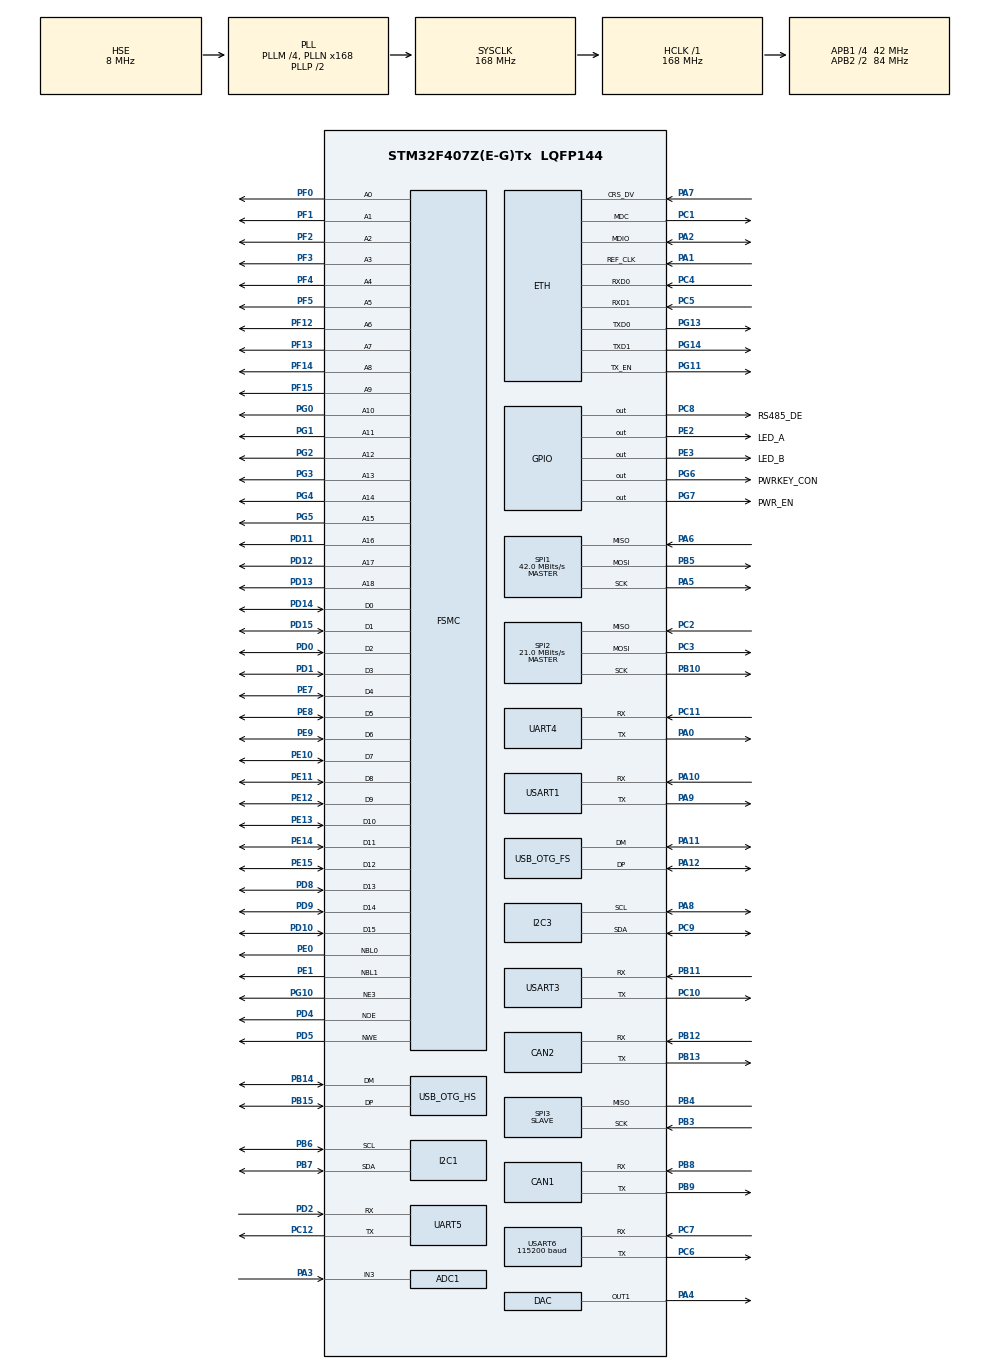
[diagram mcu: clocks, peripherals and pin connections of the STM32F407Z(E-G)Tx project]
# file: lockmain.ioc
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ADC1.Channel-0\#ChannelRegularConversion=ADC_CHANNEL_3
ADC1.NbrOfConversionFlag=1
ADC1.Rank-0\#ChannelRegularConversion=1
ADC1.SamplingTime-0\#ChannelRegularConversion=ADC_SAMPLETIME_3CYCLES
ADC1.master=1
CAN1.CalculateTimeQuantum=380.95238095238096
CAN2.CalculateTimeQuantum=380.95238095238096
ETH.MediaInterface=ETH_MEDIA_INTERFACE_RMII
FREERTOS.BinarySemaphores01=myBinarySem01,Dynamic,NULL
FREERTOS.CountingSemaphores01=myCountingSem01,2,Dynamic,NULL
FREERTOS.HEAP_NUMBER=4
FREERTOS.INCLUDE_eTaskGetState=1
FREERTOS.INCLUDE_pcTaskGetTaskName=1
FREERTOS.INCLUDE_uxTaskGetStackHighWaterMark=1
FREERTOS.INCLUDE_vTaskCleanUpResources=1
FREERTOS.INCLUDE_vTaskDelayUntil=1
FREERTOS.INCLUDE_xEventGroupSetBitFromISR=1
FREERTOS.INCLUDE_xQueueGetMutexHolder=1
FREERTOS.INCLUDE_xSemaphoreGetMutexHolder=1
FREERTOS.INCLUDE_xTaskAbortDelay=1
FREERTOS.INCLUDE_xTaskGetCurrentTaskHandle=1
FREERTOS.INCLUDE_xTaskGetHandle=1
FREERTOS.INCLUDE_xTimerPendFunctionCall=1
FREERTOS.Mutexes01=myMutex01,Dynamic,NULL
FREERTOS.Queues01=defaultQueue,16,uint16_t,0,Dynamic,NULL,NULL
FREERTOS.Tasks01=defaultTask,24,128,StartDefaultTask,Default,NULL,Dynamic,NULL,NULL
FREERTOS.Timers01=defultTimer01,Callback01,osTimerPeriodic,Default,NULL,Dynamic,NULL
FREERTOS.configGENERATE_RUN_TIME_STATS=1
FREERTOS.configUSE_STATS_FORMATTING_FUNCTIONS=1
FREERTOS.configUSE_TICKLESS_IDLE=1
FREERTOS.configUSE_TRACE_FACILITY=1
Mcu.Family=STM32F4
Mcu.Name=STM32F407Z(E-G)Tx
Mcu.Package=LQFP144
NVIC.PriorityGroup=NVIC_PRIORITYGROUP_4
NVIC.TIM8_TRG_COM_TIM14_IRQn=true\:0\:0\:false\:false\:true\:false\:false\:true
NVIC.TimeBase=TIM8_TRG_COM_TIM14_IRQn
NVIC.TimeBaseIP=TIM14
NVIC.UART4_IRQn=true\:5\:0\:false\:false\:true\:true\:true\:true
NVIC.USART1_IRQn=true\:5\:0\:false\:false\:true\:true\:true\:true
NVIC.USART6_IRQn=true\:5\:0\:false\:false\:true\:true\:true\:true
PA0-WKUP.Mode=Asynchronous
PA0-WKUP.Signal=UART4_TX
PA1.Mode=RMII
PA1.Signal=ETH_REF_CLK
PA10.Mode=Asynchronous
PA10.Signal=USART1_RX
PA11.Mode=Host_Only
PA11.Signal=USB_OTG_FS_DM
PA12.Mode=Host_Only
PA12.Signal=USB_OTG_FS_DP
PA13.Mode=Serial_Wire
PA13.Signal=SYS_JTMS-SWDIO
PA14.Mode=Serial_Wire
PA14.Signal=SYS_JTCK-SWCLK
PA2.Mode=RMII
PA2.Signal=ETH_MDIO
PA3.Signal=ADCx_IN3
PA4.Signal=COMP_DAC1_group
PA5.Mode=Full_Duplex_Master
PA5.Signal=SPI1_SCK
PA6.Mode=Full_Duplex_Master
PA6.Signal=SPI1_MISO
PA7.Mode=RMII
PA7.Signal=ETH_CRS_DV
PA8.Mode=I2C
PA8.Signal=I2C3_SCL
PA9.Mode=Asynchronous
PA9.Signal=USART1_TX
PB10.Mode=Full_Duplex_Master
PB10.Signal=SPI2_SCK
PB11.Mode=Asynchronous
PB11.Signal=USART3_RX
PB12.Mode=Slave
PB12.Signal=CAN2_RX
PB13.Mode=Slave
PB13.Signal=CAN2_TX
PB14.Mode=Device_Only_FS
PB14.Signal=USB_OTG_HS_DM
PB15.Mode=Device_Only_FS
PB15.Signal=USB_OTG_HS_DP
PB3.Mode=Simplex_Bidirectional_Slave
PB3.Signal=SPI3_SCK
PB4.Mode=Simplex_Bidirectional_Slave
PB4.Signal=SPI3_MISO
PB5.Mode=Full_Duplex_Master
PB5.Signal=SPI1_MOSI
PB6.Mode=I2C
PB6.Signal=I2C1_SCL
PB7.Mode=I2C
PB7.Signal=I2C1_SDA
PB8.Mode=Master
PB8.Signal=CAN1_RX
PB9.Mode=Master
PB9.Signal=CAN1_TX
PC1.Mode=RMII
PC1.Signal=ETH_MDC
PC10.Mode=Asynchronous
PC10.Signal=USART3_TX
PC11.Mode=Asynchronous
PC11.Signal=UART4_RX
PC12.Mode=Asynchronous
PC12.Signal=UART5_TX
PC14-OSC32_IN.Mode=LSE-External-Oscillator
PC14-OSC32_IN.Signal=RCC_OSC32_IN
PC15-OSC32_OUT.Mode=LSE-External-Oscillator
PC15-OSC32_OUT.Signal=RCC_OSC32_OUT
PC2.Mode=Full_Duplex_Master
PC2.Signal=SPI2_MISO
PC3.Mode=Full_Duplex_Master
PC3.Signal=SPI2_MOSI
PC4.Mode=RMII
PC4.Signal=ETH_RXD0
PC5.Mode=RMII
PC5.Signal=ETH_RXD1
PC6.Mode=Asynchronous
PC6.Signal=USART6_TX
PC7.Mode=Asynchronous
PC7.Signal=USART6_RX
PC8.GPIO_Label=RS485_DE
PC8.Signal=GPIO_Output
PC9.Mode=I2C
PC9.Signal=I2C3_SDA
PD0.Signal=FSMC_D2_DA2
PD1.Signal=FSMC_D3_DA3
PD10.Signal=FSMC_D15_DA15
PD11.Signal=FSMC_A16_CLE
PD12.Signal=FSMC_A17_ALE
PD13.Signal=FSMC_A18
PD14.Signal=FSMC_D0_DA0
PD15.Signal=FSMC_D1_DA1
PD2.Mode=Asynchronous
PD2.Signal=UART5_RX
PD4.Signal=FSMC_NOE
PD5.Signal=FSMC_NWE
PD8.Signal=FSMC_D13_DA13
PD9.Signal=FSMC_D14_DA14
PE0.Signal=FSMC_NBL0
PE1.Signal=FSMC_NBL1
PE10.Signal=FSMC_D7_DA7
PE11.Signal=FSMC_D8_DA8
PE12.Signal=FSMC_D9_DA9
PE13.Signal=FSMC_D10_DA10
PE14.Signal=FSMC_D11_DA11
PE15.Signal=FSMC_D12_DA12
PE2.GPIO_Label=LED_A
PE2.Signal=GPIO_Output
PE3.GPIO_Label=LED_B
PE3.Signal=GPIO_Output
PE7.Signal=FSMC_D4_DA4
PE8.Signal=FSMC_D5_DA5
PE9.Signal=FSMC_D6_DA6
PF0.Signal=FSMC_A0
PF1.Signal=FSMC_A1
PF12.Signal=FSMC_A6
PF13.Signal=FSMC_A7
PF14.Signal=FSMC_A8
PF15.Signal=FSMC_A9
PF2.Signal=FSMC_A2
PF3.Signal=FSMC_A3
PF4.Signal=FSMC_A4
PF5.Signal=FSMC_A5
PG0.Signal=FSMC_A10
PG1.Signal=FSMC_A11
PG10.Mode=NorPsramChipSelect3_1
PG10.Signal=FSMC_NE3
PG11.Mode=RMII
PG11.Signal=ETH_TX_EN
PG13.Mode=RMII
PG13.Signal=ETH_TXD0
PG14.Mode=RMII
PG14.Signal=ETH_TXD1
PG2.Signal=FSMC_A12
PG3.Signal=FSMC_A13
PG4.Signal=FSMC_A14
PG5.Signal=FSMC_A15
PG6.GPIO_Label=PWRKEY_CON
PG6.Signal=GPIO_Output
PG7.GPIO_Label=PWR_EN
PG7.Signal=GPIO_Output
PH0-OSC_IN.Mode=HSE-External-Oscillator
PH0-OSC_IN.Signal=RCC_OSC_IN
PH1-OSC_OUT.Mode=HSE-External-Oscillator
PH1-OSC_OUT.Signal=RCC_OSC_OUT
ProjectManager.HeapSize=0x200
ProjectManager.StackSize=0x400
ProjectManager.TargetToolchain=MDK-ARM V5
RCC.48MHZClocksFreq_Value=48000000
RCC.AHBFreq_Value=168000000
RCC.APB1CLKDivider=RCC_HCLK_DIV4
RCC.APB1Freq_Value=42000000
RCC.APB1TimFreq_Value=84000000
RCC.APB2CLKDivider=RCC_HCLK_DIV2
RCC.APB2Freq_Value=84000000
RCC.APB2TimFreq_Value=168000000
RCC.CortexFreq_Value=168000000
RCC.HCLKFreq_Value=168000000
RCC.HSE_VALUE=8000000
RCC.HSI_VALUE=16000000
RCC.PLLM=4
RCC.PLLN=168
RCC.PLLQ=7
RCC.RCC_RTC_Clock_Source=RCC_RTCCLKSOURCE_LSE
RCC.RCC_RTC_Clock_SourceVirtual=RCC_RTCCLKSOURCE_LSE
RCC.SYSCLKFreq_VALUE=168000000
RCC.SYSCLKSource=RCC_SYSCLKSOURCE_PLLCLK
RCC.VCOOutputFreq_Value=336000000
SH.ADCx_IN3.0=ADC1_IN3,IN3
SH.COMP_DAC1_group.0=DAC_OUT1,DAC_OUT1
SH.FSMC_A0.0=FSMC_A0,19b-a1
SH.FSMC_A1.0=FSMC_A1,19b-a1
SH.FSMC_A10.0=FSMC_A10,19b-a1
SH.FSMC_A11.0=FSMC_A11,19b-a1
SH.FSMC_A12.0=FSMC_A12,19b-a1
SH.FSMC_A13.0=FSMC_A13,19b-a1
SH.FSMC_A14.0=FSMC_A14,19b-a1
SH.FSMC_A15.0=FSMC_A15,19b-a1
SH.FSMC_A16_CLE.0=FSMC_A16,19b-a1
SH.FSMC_A17_ALE.0=FSMC_A17,19b-a1
SH.FSMC_A18.0=FSMC_A18,19b-a1
SH.FSMC_A2.0=FSMC_A2,19b-a1
SH.FSMC_A3.0=FSMC_A3,19b-a1
SH.FSMC_A4.0=FSMC_A4,19b-a1
SH.FSMC_A5.0=FSMC_A5,19b-a1
SH.FSMC_A6.0=FSMC_A6,19b-a1
SH.FSMC_A7.0=FSMC_A7,19b-a1
SH.FSMC_A8.0=FSMC_A8,19b-a1
SH.FSMC_A9.0=FSMC_A9,19b-a1
SH.FSMC_D0_DA0.0=FSMC_D0,16b-d1
SH.FSMC_D10_DA10.0=FSMC_D10,16b-d1
SH.FSMC_D11_DA11.0=FSMC_D11,16b-d1
SH.FSMC_D12_DA12.0=FSMC_D12,16b-d1
SH.FSMC_D13_DA13.0=FSMC_D13,16b-d1
SH.FSMC_D14_DA14.0=FSMC_D14,16b-d1
SH.FSMC_D15_DA15.0=FSMC_D15,16b-d1
SH.FSMC_D1_DA1.0=FSMC_D1,16b-d1
SH.FSMC_D2_DA2.0=FSMC_D2,16b-d1
SH.FSMC_D3_DA3.0=FSMC_D3,16b-d1
SH.FSMC_D4_DA4.0=FSMC_D4,16b-d1
SH.FSMC_D5_DA5.0=FSMC_D5,16b-d1
SH.FSMC_D6_DA6.0=FSMC_D6,16b-d1
SH.FSMC_D7_DA7.0=FSMC_D7,16b-d1
SH.FSMC_D8_DA8.0=FSMC_D8,16b-d1
SH.FSMC_D9_DA9.0=FSMC_D9,16b-d1
SH.FSMC_NBL0.0=FSMC_NBL0,2ByteEnable1
SH.FSMC_NBL1.0=FSMC_NBL1,2ByteEnable1
SH.FSMC_NOE.0=FSMC_NOE,Sram1
SH.FSMC_NWE.0=FSMC_NWE,Sram1
SPI1.CalculateBaudRate=42.0 MBits/s
SPI1.Direction=SPI_DIRECTION_2LINES
SPI1.Mode=SPI_MODE_MASTER
SPI1.VirtualType=VM_MASTER
SPI2.CalculateBaudRate=21.0 MBits/s
SPI2.Direction=SPI_DIRECTION_2LINES
SPI2.Mode=SPI_MODE_MASTER
SPI2.VirtualType=VM_MASTER
SPI3.Direction=SPI_DIRECTION_1LINE
SPI3.Mode=SPI_MODE_SLAVE
SPI3.VirtualType=VM_SLAVE
UART4.VirtualMode=Asynchronous
UART5.VirtualMode=Asynchronous
USART1.VirtualMode=VM_ASYNC
USART3.VirtualMode=VM_ASYNC
USART6.BaudRate=115200
USART6.VirtualMode=VM_ASYNC
USB_OTG_FS.VirtualMode=Host_Only
USB_OTG_FS.phy_itface=HCD_PHY_EMBEDDED
USB_OTG_HS.VirtualMode-Device_Only_FS=Device_Only_FS
VP_FREERTOS_VS_CMSIS_V2.Mode=CMSIS_V2
VP_RTC_VS_RTC_Activate.Mode=RTC_Enabled
VP_RTC_VS_RTC_Calendar.Mode=RTC_Calendar
VP_SYS_VS_tim14.Mode=TIM14
board=custom

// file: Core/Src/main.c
/* USER CODE BEGIN Header */
/**
  ******************************************************************************
  * @file           : main.c
  * @brief          : Main program body
  ******************************************************************************
  * @attention
  *
  * <h2><center>&copy; Copyright (c) 2019 STMicroelectronics.
  * All rights reserved.</center></h2>
  *
  * This software component is licensed by ST under Ultimate Liberty license
  * SLA0044, the "License"; You may not use this file except in compliance with
  * the License. You may obtain a copy of the License at:
  *                             www.st.com/SLA0044
  *
  ******************************************************************************
  */
/* USER CODE END Header */

#include "main.h"
#include "cmsis_os.h"

/* USER CODE BEGIN Includes */
#include "gprs.h"
#include "util.h"
#include "rs485.h"
#include "para.h"
#include "debug.h"

#define COMPID "MAIN"
/* USER CODE END Includes */

/* USER CODE BEGIN PTD */
static AppTask_t app;//realsil test
RTC_TimeTypeDef rtcTime;
RTC_DateTypeDef rtcDate;
// static SysMsg_t appMsg;
// static SysMsgThread_t appMsgThread;
SysMsg_t appMsg;//
/* USER CODE END PTD */

ADC_HandleTypeDef hadc1;

CAN_HandleTypeDef hcan1;
CAN_HandleTypeDef hcan2;

DAC_HandleTypeDef hdac;

ETH_HandleTypeDef heth;

I2C_HandleTypeDef hi2c1;
I2C_HandleTypeDef hi2c3;

RTC_HandleTypeDef hrtc;

SPI_HandleTypeDef hspi1;
SPI_HandleTypeDef hspi2;
SPI_HandleTypeDef hspi3;

UART_HandleTypeDef huart4;
UART_HandleTypeDef huart5;
UART_HandleTypeDef huart1;
UART_HandleTypeDef huart3;
UART_HandleTypeDef huart6;

HCD_HandleTypeDef hhcd_USB_OTG_FS;
PCD_HandleTypeDef hpcd_USB_OTG_HS;

SRAM_HandleTypeDef hsram1;

osThreadId_t defaultTaskHandle;
osMessageQueueId_t defaultQueueHandle;
osTimerId_t defultTimer01Handle;
osMutexId_t myMutex01Handle;
osSemaphoreId_t myBinarySem01Handle;
osSemaphoreId_t myCountingSem01Handle;

void SystemClock_Config(void);
static void MX_GPIO_Init(void);
static void MX_ETH_Init(void);
static void MX_ADC1_Init(void);
static void MX_CAN1_Init(void);
static void MX_CAN2_Init(void);
static void MX_DAC_Init(void);
static void MX_FSMC_Init(void);
static void MX_I2C1_Init(void);
static void MX_I2C3_Init(void);
static void MX_RTC_Init(void);
static void MX_SPI1_Init(void);
static void MX_SPI2_Init(void);
static void MX_SPI3_Init(void);
static void MX_UART4_Init(void);
static void MX_UART5_Init(void);
static void MX_USART1_UART_Init(void);
static void MX_USART3_UART_Init(void);
static void MX_USART6_UART_Init(void);
static void MX_USB_OTG_FS_HCD_Init(void);
static void MX_USB_OTG_HS_PCD_Init(void);
void StartDefaultTask(void *argument); // for v2
void Callback01(void *argument); // for v2

/* USER CODE BEGIN PFP */
osThreadId_t appTaskHandle;
osMessageQueueId_t appMsgHandle;
/* USER CODE END PFP */

/* USER CODE BEGIN 0 */
static void AppMgrInit(void)
{
  const osThreadAttr_t appTask_attributes = {
    .name = NAME_TASK_APP,
    .priority = (osPriority_t) PRIO_TASK_APP,
    .stack_size = STACK_SIZE_TASK_APP
  };
  appTaskHandle = osThreadNew(AppTask,NULL,&appTask_attributes);

  const osMessageQueueAttr_t appMsg_attributes = {
    .name = NAME_MSG_APP
  };
  appMsgHandle = osMessageQueueNew(APP_MSG_NUM,sizeof(SysMsg_t),&appMsg_attributes);
  // appMsg.src = SysMsgSrc_Thread;
  // appMsg.thread = &appMsgThread;
}

static void AppInit (void)
{
  // AppParaInit();
  SystemLoadActionParamOnce();
  AppMgrInit();
  GprsMgrInit();
  RS485MgrInit();
  DebugMgrInit();
}

AppTask_t *GetApp(void)
{
    return &app;//i am sorry
}

void MXUsart1UartInit()  {MX_USART1_UART_Init();}
void MXUsart3UartInit()  {MX_USART3_UART_Init();}
void MXUsart4UartInit()  {MX_UART4_Init();}
void MXUsart5UartInit()  {MX_UART5_Init();}
void MXUsart6UartInit()  {MX_USART6_UART_Init();}

static void AppUartMsgHandle(SysMsgUart_t* msgUart);
static void AppThreadHandle(SysMsgThread_t* msgThread);

void AppTask(void *argument)
{
	SysMsg_t msg;
  for(;;)
  {
    if(osMessageQueueGet(appMsgHandle,&msg,NULL,osWaitForever)==osOK)
    {
      if (msg.src == SysMsgSrc_Uart)
      {
        AppUartMsgHandle(&msg.uart);
      }
      else if(msg.src == SysMsgSrc_Thread)
      {
        AppThreadHandle(&msg.thread);
      }
    }
  }
}

void AppUartMsgHandle(SysMsgUart_t* msgUart)
{

}

static USER_ERROR_CODE AppThreadHandleIdle(SysMsgThread_t* msgThread);
static USER_ERROR_CODE AppThreadHandleSysInit(SysMsgThread_t* msgThread);
//定义函数数组,用于网口处理线程回调
static const TaskHandlePtrWithThread AppThreadHandleArray[] = {
	AppThreadHandleIdle,
	AppThreadHandleSysInit,
};
#define APP_THREAD_HANDLE_COUNT_MAX      (sizeof(AppThreadHandleArray)/sizeof(AppThreadHandleArray[0]))

USER_ERROR_CODE AppThreadHandleIdle(SysMsgThread_t* msgThread)
{
  USER_ERROR_CODE errorCode = USER_ERROR_NONE;

  return errorCode;
}

USER_ERROR_CODE AppThreadHandleSysInit(SysMsgThread_t* msgThread)
{
  USER_ERROR_CODE errorCode = USER_ERROR_NONE;

  gprsMsg.src = SysMsgSrc_Thread;
  gprsMsg.thread.id = GPRS_MSG_Init;
  do
  {
    osMessageQueuePut(gprsMsgHandle,&gprsMsg,NULL,osWaitForever);
    osThreadFlagsWait(APP_FLAG_MASK_GPRS_INIT,osFlagsWaitAll,osWaitForever);
  }while(!app.gprsConnected);

  rs485Msg.src = SysMsgSrc_Thread;
  rs485Msg.thread.id = RS485_MSG_Init;
  osMessageQueuePut(rs485MsgHandle,&rs485Msg,NULL,osWaitForever);
  osThreadFlagsWait(APP_FLAG_MASK_RS485_INIT,osFlagsWaitAll,osWaitForever);
  //运行到此，说明硬件初始化完成
  app.AppStatus = hardwareReady;
  return errorCode;
}

void AppThreadHandle(SysMsgThread_t* msgThread)
{
  uint8_t index;
  uint8_t msgId;

  msgId = msgThread->id;

  index = msgId - APP_MSG_BASE;
	USER_ERROR_CODE errorCode;

	if(index > APP_THREAD_HANDLE_COUNT_MAX)
	{
		errorCode = USER_ID_NO_SUPPORT;

    return;
	}
	errorCode = AppThreadHandleArray[index](msgThread);
	LOGA("errorCode is %x",errorCode);

}

/* USER CODE END 0 */

int main(void)
{
  /* USER CODE BEGIN 1 */
  app.AppStatus=poweringOn;
  /* USER CODE END 1 */

  /* MCU Configuration--------------------------------------------------------*/

  /* Reset of all peripherals, Initializes the Flash interface and the Systick. */
  HAL_Init();

  /* Configure the system clock */
  SystemClock_Config();

  /* Initialize all configured peripherals */
  MX_GPIO_Init();
  MX_ETH_Init();
  MX_ADC1_Init();
  MX_CAN1_Init();
  MX_CAN2_Init();
  MX_DAC_Init();
  MX_FSMC_Init();
  MX_I2C1_Init();
  MX_I2C3_Init();
  MX_RTC_Init();
  MX_SPI1_Init();
  MX_SPI2_Init();
  MX_SPI3_Init();
  MX_UART4_Init();
  MX_UART5_Init();
  MX_USART1_UART_Init();
  MX_USART3_UART_Init();
  MX_USART6_UART_Init();
  MX_USB_OTG_FS_HCD_Init();
  MX_USB_OTG_HS_PCD_Init();
  /* USER CODE BEGIN 2 */
  app.AppStatus=initialising;
  /* USER CODE END 2 */

  osKernelInitialize(); // Initialize CMSIS-RTOS

  /* Create the mutex(es) */
  /* definition and creation of myMutex01 */
  const osMutexAttr_t myMutex01_attributes = {
    .name = "myMutex01"
  };
  myMutex01Handle = osMutexNew(&myMutex01_attributes);

  /* Create the semaphores(s) */
  /* definition and creation of myBinarySem01 */
  const osSemaphoreAttr_t myBinarySem01_attributes = {
    .name = "myBinarySem01"
  };
  myBinarySem01Handle = osSemaphoreNew(1, 1, &myBinarySem01_attributes);

  /* definition and creation of myCountingSem01 */
  const osSemaphoreAttr_t myCountingSem01_attributes = {
    .name = "myCountingSem01"
  };
  myCountingSem01Handle = osSemaphoreNew(2, 2, &myCountingSem01_attributes);

  /* Create the timer(s) */
  /* definition and creation of defultTimer01 */
  const osTimerAttr_t defultTimer01_attributes = {
    .name = "defultTimer01"
  };
  defultTimer01Handle = osTimerNew(Callback01, osTimerPeriodic, NULL, &defultTimer01_attributes);

  /* Create the queue(s) */
  /* definition and creation of defaultQueue */
  const osMessageQueueAttr_t defaultQueue_attributes = {
    .name = "defaultQueue"
  };
  defaultQueueHandle = osMessageQueueNew (16, sizeof(uint16_t), &defaultQueue_attributes);

  /* Create the thread(s) */
  /* definition and creation of defaultTask */
  const osThreadAttr_t defaultTask_attributes = {
    .name = "defaultTask",
    .priority = (osPriority_t) osPriorityNormal,
    .stack_size = 128
  };
  defaultTaskHandle = osThreadNew(StartDefaultTask, NULL, &defaultTask_attributes);

  /* USER CODE BEGIN RTOS_THREADS */
  /* add threads, ... */
  AppInit();
  app.AppStatus=initialised;
  /* USER CODE END RTOS_THREADS */

  /* Start scheduler */
  osKernelStart();

  /* We should never get here as control is now taken by the scheduler */

  /* Infinite loop */
  while (1)
  {

  }
}

void SystemClock_Config(void)
{
  RCC_OscInitTypeDef RCC_OscInitStruct = {0};
  RCC_ClkInitTypeDef RCC_ClkInitStruct = {0};
  RCC_PeriphCLKInitTypeDef PeriphClkInitStruct = {0};

  /** Configure the main internal regulator output voltage
  */
  __HAL_RCC_PWR_CLK_ENABLE();
  __HAL_PWR_VOLTAGESCALING_CONFIG(PWR_REGULATOR_VOLTAGE_SCALE1);
  /** Initializes the CPU, AHB and APB busses clocks
  */
  RCC_OscInitStruct.OscillatorType = RCC_OSCILLATORTYPE_HSE|RCC_OSCILLATORTYPE_LSE;
  RCC_OscInitStruct.HSEState = RCC_HSE_ON;
  RCC_OscInitStruct.LSEState = RCC_LSE_ON;
  RCC_OscInitStruct.PLL.PLLState = RCC_PLL_ON;
  RCC_OscInitStruct.PLL.PLLSource = RCC_PLLSOURCE_HSE;
  RCC_OscInitStruct.PLL.PLLM = 4;
  RCC_OscInitStruct.PLL.PLLN = 168;
  RCC_OscInitStruct.PLL.PLLP = RCC_PLLP_DIV2;
  RCC_OscInitStruct.PLL.PLLQ = 7;
  if (HAL_RCC_OscConfig(&RCC_OscInitStruct) != HAL_OK)
  {
    Error_Handler();
  }
  /** Initializes the CPU, AHB and APB busses clocks
  */
  RCC_ClkInitStruct.ClockType = RCC_CLOCKTYPE_HCLK|RCC_CLOCKTYPE_SYSCLK
                              |RCC_CLOCKTYPE_PCLK1|RCC_CLOCKTYPE_PCLK2;
  RCC_ClkInitStruct.SYSCLKSource = RCC_SYSCLKSOURCE_PLLCLK;
  RCC_ClkInitStruct.AHBCLKDivider = RCC_SYSCLK_DIV1;
  RCC_ClkInitStruct.APB1CLKDivider = RCC_HCLK_DIV4;
  RCC_ClkInitStruct.APB2CLKDivider = RCC_HCLK_DIV2;

  if (HAL_RCC_ClockConfig(&RCC_ClkInitStruct, FLASH_LATENCY_5) != HAL_OK)
  {
    Error_Handler();
  }
  PeriphClkInitStruct.PeriphClockSelection = RCC_PERIPHCLK_RTC;
  PeriphClkInitStruct.RTCClockSelection = RCC_RTCCLKSOURCE_LSE;
  if (HAL_RCCEx_PeriphCLKConfig(&PeriphClkInitStruct) != HAL_OK)
  {
    Error_Handler();
  }
}

static void MX_ADC1_Init(void)
{

  ADC_ChannelConfTypeDef sConfig = {0};

  /** Configure the global features of the ADC (Clock, Resolution, Data Alignment and number of conversion)
  */
  hadc1.Instance = ADC1;
  hadc1.Init.ClockPrescaler = ADC_CLOCK_SYNC_PCLK_DIV4;
  hadc1.Init.Resolution = ADC_RESOLUTION_12B;
  hadc1.Init.ScanConvMode = DISABLE;
  hadc1.Init.ContinuousConvMode = DISABLE;
  hadc1.Init.DiscontinuousConvMode = DISABLE;
  hadc1.Init.ExternalTrigConvEdge = ADC_EXTERNALTRIGCONVEDGE_NONE;
  hadc1.Init.ExternalTrigConv = ADC_SOFTWARE_START;
  hadc1.Init.DataAlign = ADC_DATAALIGN_RIGHT;
  hadc1.Init.NbrOfConversion = 1;
  hadc1.Init.DMAContinuousRequests = DISABLE;
  hadc1.Init.EOCSelection = ADC_EOC_SINGLE_CONV;
  if (HAL_ADC_Init(&hadc1) != HAL_OK)
  {
    Error_Handler();
  }
  /** Configure for the selected ADC regular channel its corresponding rank in the sequencer and its sample time.
  */
  sConfig.Channel = ADC_CHANNEL_3;
  sConfig.Rank = 1;
  sConfig.SamplingTime = ADC_SAMPLETIME_3CYCLES;
  if (HAL_ADC_ConfigChannel(&hadc1, &sConfig) != HAL_OK)
  {
    Error_Handler();
  }

}

static void MX_CAN1_Init(void)
{

  hcan1.Instance = CAN1;
  hcan1.Init.Prescaler = 16;
  hcan1.Init.Mode = CAN_MODE_NORMAL;
  hcan1.Init.SyncJumpWidth = CAN_SJW_1TQ;
  hcan1.Init.TimeSeg1 = CAN_BS1_1TQ;
  hcan1.Init.TimeSeg2 = CAN_BS2_1TQ;
  hcan1.Init.TimeTriggeredMode = DISABLE;
  hcan1.Init.AutoBusOff = DISABLE;
  hcan1.Init.AutoWakeUp = DISABLE;
  hcan1.Init.AutoRetransmission = DISABLE;
  hcan1.Init.ReceiveFifoLocked = DISABLE;
  hcan1.Init.TransmitFifoPriority = DISABLE;
  if (HAL_CAN_Init(&hcan1) != HAL_OK)
  {
    Error_Handler();
  }

}

static void MX_CAN2_Init(void)
{

  hcan2.Instance = CAN2;
  hcan2.Init.Prescaler = 16;
  hcan2.Init.Mode = CAN_MODE_NORMAL;
  hcan2.Init.SyncJumpWidth = CAN_SJW_1TQ;
  hcan2.Init.TimeSeg1 = CAN_BS1_1TQ;
  hcan2.Init.TimeSeg2 = CAN_BS2_1TQ;
  hcan2.Init.TimeTriggeredMode = DISABLE;
  hcan2.Init.AutoBusOff = DISABLE;
  hcan2.Init.AutoWakeUp = DISABLE;
  hcan2.Init.AutoRetransmission = DISABLE;
  hcan2.Init.ReceiveFifoLocked = DISABLE;
  hcan2.Init.TransmitFifoPriority = DISABLE;
  if (HAL_CAN_Init(&hcan2) != HAL_OK)
  {
    Error_Handler();
  }

}

static void MX_DAC_Init(void)
{

  DAC_ChannelConfTypeDef sConfig = {0};

  /** DAC Initialization
  */
  hdac.Instance = DAC;
  if (HAL_DAC_Init(&hdac) != HAL_OK)
  {
    Error_Handler();
  }
  /** DAC channel OUT1 config
  */
  sConfig.DAC_Trigger = DAC_TRIGGER_NONE;
  sConfig.DAC_OutputBuffer = DAC_OUTPUTBUFFER_ENABLE;
  if (HAL_DAC_ConfigChannel(&hdac, &sConfig, DAC_CHANNEL_1) != HAL_OK)
  {
    Error_Handler();
  }

}

static void MX_ETH_Init(void)
{

   uint8_t MACAddr[6] ;

  heth.Instance = ETH;
  heth.Init.AutoNegotiation = ETH_AUTONEGOTIATION_ENABLE;
  heth.Init.PhyAddress = LAN8742A_PHY_ADDRESS;
  MACAddr[0] = 0x00;
  MACAddr[1] = 0x80;
  MACAddr[2] = 0xE1;
  MACAddr[3] = 0x00;
  MACAddr[4] = 0x00;
  MACAddr[5] = 0x00;
  heth.Init.MACAddr = &MACAddr[0];
  heth.Init.RxMode = ETH_RXPOLLING_MODE;
  heth.Init.ChecksumMode = ETH_CHECKSUM_BY_HARDWARE;
  heth.Init.MediaInterface = ETH_MEDIA_INTERFACE_RMII;

  if (HAL_ETH_Init(&heth) != HAL_OK)
  {
    Error_Handler();
  }

}

static void MX_I2C1_Init(void)
{

  hi2c1.Instance = I2C1;
  hi2c1.Init.ClockSpeed = 100000;
  hi2c1.Init.DutyCycle = I2C_DUTYCYCLE_2;
  hi2c1.Init.OwnAddress1 = 0;
  hi2c1.Init.AddressingMode = I2C_ADDRESSINGMODE_7BIT;
  hi2c1.Init.DualAddressMode = I2C_DUALADDRESS_DISABLE;
  hi2c1.Init.OwnAddress2 = 0;
  hi2c1.Init.GeneralCallMode = I2C_GENERALCALL_DISABLE;
  hi2c1.Init.NoStretchMode = I2C_NOSTRETCH_DISABLE;
  if (HAL_I2C_Init(&hi2c1) != HAL_OK)
  {
    Error_Handler();
  }

}

static void MX_I2C3_Init(void)
{

  hi2c3.Instance = I2C3;
  hi2c3.Init.ClockSpeed = 100000;
  hi2c3.Init.DutyCycle = I2C_DUTYCYCLE_2;
  hi2c3.Init.OwnAddress1 = 0;
  hi2c3.Init.AddressingMode = I2C_ADDRESSINGMODE_7BIT;
  hi2c3.Init.DualAddressMode = I2C_DUALADDRESS_DISABLE;
  hi2c3.Init.OwnAddress2 = 0;
  hi2c3.Init.GeneralCallMode = I2C_GENERALCALL_DISABLE;
  hi2c3.Init.NoStretchMode = I2C_NOSTRETCH_DISABLE;
  if (HAL_I2C_Init(&hi2c3) != HAL_OK)
  {
    Error_Handler();
  }

}

static void MX_RTC_Init(void)
{

  RTC_TimeTypeDef sTime = {0};
  RTC_DateTypeDef sDate = {0};

  /** Initialize RTC Only
  */
  hrtc.Instance = RTC;
  hrtc.Init.HourFormat = RTC_HOURFORMAT_24;
  hrtc.Init.AsynchPrediv = 127;
  hrtc.Init.SynchPrediv = 255;
  hrtc.Init.OutPut = RTC_OUTPUT_DISABLE;
  hrtc.Init.OutPutPolarity = RTC_OUTPUT_POLARITY_HIGH;
  hrtc.Init.OutPutType = RTC_OUTPUT_TYPE_OPENDRAIN;
  if (HAL_RTC_Init(&hrtc) != HAL_OK)
  {
    Error_Handler();
  }

  /** Initialize RTC and set the Time and Date
  */
  sTime.Hours = 0x0;
  sTime.Minutes = 0x0;
  sTime.Seconds = 0x0;
  sTime.DayLightSaving = RTC_DAYLIGHTSAVING_NONE;
  sTime.StoreOperation = RTC_STOREOPERATION_RESET;
  if (HAL_RTC_SetTime(&hrtc, &sTime, RTC_FORMAT_BCD) != HAL_OK)
  {
    Error_Handler();
  }
  sDate.WeekDay = RTC_WEEKDAY_MONDAY;
  sDate.Month = RTC_MONTH_JANUARY;
  sDate.Date = 0x1;
  sDate.Year = 0x0;

  if (HAL_RTC_SetDate(&hrtc, &sDate, RTC_FORMAT_BCD) != HAL_OK)
  {
    Error_Handler();
  }

}

static void MX_SPI1_Init(void)
{

  /* SPI1 parameter configuration*/
  hspi1.Instance = SPI1;
  hspi1.Init.Mode = SPI_MODE_MASTER;
  hspi1.Init.Direction = SPI_DIRECTION_2LINES;
  hspi1.Init.DataSize = SPI_DATASIZE_8BIT;
  hspi1.Init.CLKPolarity = SPI_POLARITY_LOW;
  hspi1.Init.CLKPhase = SPI_PHASE_1EDGE;
  hspi1.Init.NSS = SPI_NSS_SOFT;
  hspi1.Init.BaudRatePrescaler = SPI_BAUDRATEPRESCALER_2;
  hspi1.Init.FirstBit = SPI_FIRSTBIT_MSB;
  hspi1.Init.TIMode = SPI_TIMODE_DISABLE;
  hspi1.Init.CRCCalculation = SPI_CRCCALCULATION_DISABLE;
  hspi1.Init.CRCPolynomial = 10;
  if (HAL_SPI_Init(&hspi1) != HAL_OK)
  {
    Error_Handler();
  }

}

static void MX_SPI2_Init(void)
{

  /* SPI2 parameter configuration*/
  hspi2.Instance = SPI2;
  hspi2.Init.Mode = SPI_MODE_MASTER;
  hspi2.Init.Direction = SPI_DIRECTION_2LINES;
  hspi2.Init.DataSize = SPI_DATASIZE_8BIT;
  hspi2.Init.CLKPolarity = SPI_POLARITY_LOW;
  hspi2.Init.CLKPhase = SPI_PHASE_1EDGE;
  hspi2.Init.NSS = SPI_NSS_SOFT;
  hspi2.Init.BaudRatePrescaler = SPI_BAUDRATEPRESCALER_2;
  hspi2.Init.FirstBit = SPI_FIRSTBIT_MSB;
  hspi2.Init.TIMode = SPI_TIMODE_DISABLE;
  hspi2.Init.CRCCalculation = SPI_CRCCALCULATION_DISABLE;
  hspi2.Init.CRCPolynomial = 10;
  if (HAL_SPI_Init(&hspi2) != HAL_OK)
  {
    Error_Handler();
  }

}

static void MX_SPI3_Init(void)
{

  /* SPI3 parameter configuration*/
  hspi3.Instance = SPI3;
  hspi3.Init.Mode = SPI_MODE_SLAVE;
  hspi3.Init.Direction = SPI_DIRECTION_1LINE;
  hspi3.Init.DataSize = SPI_DATASIZE_8BIT;
  hspi3.Init.CLKPolarity = SPI_POLARITY_LOW;
  hspi3.Init.CLKPhase = SPI_PHASE_1EDGE;
  hspi3.Init.NSS = SPI_NSS_SOFT;
  hspi3.Init.FirstBit = SPI_FIRSTBIT_MSB;
  hspi3.Init.TIMode = SPI_TIMODE_DISABLE;
  hspi3.Init.CRCCalculation = SPI_CRCCALCULATION_DISABLE;
  hspi3.Init.CRCPolynomial = 10;
  if (HAL_SPI_Init(&hspi3) != HAL_OK)
  {
    Error_Handler();
  }

}

static void MX_UART4_Init(void)
{

  huart4.Instance = UART4;
  huart4.Init.BaudRate = 115200;
  huart4.Init.WordLength = UART_WORDLENGTH_8B;
  huart4.Init.StopBits = UART_STOPBITS_1;
  huart4.Init.Parity = UART_PARITY_NONE;
  huart4.Init.Mode = UART_MODE_TX_RX;
  huart4.Init.HwFlowCtl = UART_HWCONTROL_NONE;
  huart4.Init.OverSampling = UART_OVERSAMPLING_16;
  if (HAL_UART_Init(&huart4) != HAL_OK)
  {
    Error_Handler();
  }

}

static void MX_UART5_Init(void)
{

  huart5.Instance = UART5;
  huart5.Init.BaudRate = 115200;
  huart5.Init.WordLength = UART_WORDLENGTH_8B;
  huart5.Init.StopBits = UART_STOPBITS_1;
  huart5.Init.Parity = UART_PARITY_NONE;
  huart5.Init.Mode = UART_MODE_TX_RX;
  huart5.Init.HwFlowCtl = UART_HWCONTROL_NONE;
  huart5.Init.OverSampling = UART_OVERSAMPLING_16;
  if (HAL_UART_Init(&huart5) != HAL_OK)
  {
    Error_Handler();
  }

}

static void MX_USART1_UART_Init(void)
{

  huart1.Instance = USART1;
  huart1.Init.BaudRate = 115200;
  huart1.Init.WordLength = UART_WORDLENGTH_8B;
  huart1.Init.StopBits = UART_STOPBITS_1;
  huart1.Init.Parity = UART_PARITY_NONE;
  huart1.Init.Mode = UART_MODE_TX_RX;
  huart1.Init.HwFlowCtl = UART_HWCONTROL_NONE;
  huart1.Init.OverSampling = UART_OVERSAMPLING_16;
  if (HAL_UART_Init(&huart1) != HAL_OK)
  {
    Error_Handler();
  }

}

static void MX_USART3_UART_Init(void)
{

  huart3.Instance = USART3;
  huart3.Init.BaudRate = 115200;
  huart3.Init.WordLength = UART_WORDLENGTH_8B;
  huart3.Init.StopBits = UART_STOPBITS_1;
  huart3.Init.Parity = UART_PARITY_NONE;
  huart3.Init.Mode = UART_MODE_TX_RX;
  huart3.Init.HwFlowCtl = UART_HWCONTROL_NONE;
  huart3.Init.OverSampling = UART_OVERSAMPLING_16;
  if (HAL_UART_Init(&huart3) != HAL_OK)
  {
    Error_Handler();
  }

}

static void MX_USART6_UART_Init(void)
{

  huart6.Instance = USART6;
  huart6.Init.BaudRate = 115200;
  huart6.Init.WordLength = UART_WORDLENGTH_8B;
  huart6.Init.StopBits = UART_STOPBITS_1;
  huart6.Init.Parity = UART_PARITY_NONE;
  huart6.Init.Mode = UART_MODE_TX_RX;
  huart6.Init.HwFlowCtl = UART_HWCONTROL_NONE;
  huart6.Init.OverSampling = UART_OVERSAMPLING_16;
  if (HAL_UART_Init(&huart6) != HAL_OK)
  {
    Error_Handler();
  }

}

static void MX_USB_OTG_FS_HCD_Init(void)
{

  hhcd_USB_OTG_FS.Instance = USB_OTG_FS;
  hhcd_USB_OTG_FS.Init.Host_channels = 8;
  hhcd_USB_OTG_FS.Init.speed = HCD_SPEED_FULL;
  hhcd_USB_OTG_FS.Init.dma_enable = DISABLE;
  hhcd_USB_OTG_FS.Init.phy_itface = HCD_PHY_EMBEDDED;
  hhcd_USB_OTG_FS.Init.Sof_enable = DISABLE;
  if (HAL_HCD_Init(&hhcd_USB_OTG_FS) != HAL_OK)
  {
    Error_Handler();
  }

}

static void MX_USB_OTG_HS_PCD_Init(void)
{

  hpcd_USB_OTG_HS.Instance = USB_OTG_HS;
  hpcd_USB_OTG_HS.Init.dev_endpoints = 6;
  hpcd_USB_OTG_HS.Init.speed = PCD_SPEED_FULL;
  hpcd_USB_OTG_HS.Init.dma_enable = DISABLE;
  hpcd_USB_OTG_HS.Init.phy_itface = USB_OTG_EMBEDDED_PHY;
  hpcd_USB_OTG_HS.Init.Sof_enable = DISABLE;
  hpcd_USB_OTG_HS.Init.low_power_enable = DISABLE;
  hpcd_USB_OTG_HS.Init.lpm_enable = DISABLE;
  hpcd_USB_OTG_HS.Init.vbus_sensing_enable = DISABLE;
  hpcd_USB_OTG_HS.Init.use_dedicated_ep1 = DISABLE;
  hpcd_USB_OTG_HS.Init.use_external_vbus = DISABLE;
  if (HAL_PCD_Init(&hpcd_USB_OTG_HS) != HAL_OK)
  {
    Error_Handler();
  }

}

static void MX_GPIO_Init(void)
{
  GPIO_InitTypeDef GPIO_InitStruct = {0};

  /* GPIO Ports Clock Enable */
  __HAL_RCC_GPIOE_CLK_ENABLE();
  __HAL_RCC_GPIOC_CLK_ENABLE();
  __HAL_RCC_GPIOF_CLK_ENABLE();
  __HAL_RCC_GPIOH_CLK_ENABLE();
  __HAL_RCC_GPIOA_CLK_ENABLE();
  __HAL_RCC_GPIOG_CLK_ENABLE();
  __HAL_RCC_GPIOB_CLK_ENABLE();
  __HAL_RCC_GPIOD_CLK_ENABLE();

  /*Configure GPIO pin Output Level */
  HAL_GPIO_WritePin(GPIOE, LED_A_Pin|LED_B_Pin, GPIO_PIN_RESET);

  /*Configure GPIO pin Output Level */
  HAL_GPIO_WritePin(GPIOG, PWRKEY_CON_Pin|PWR_EN_Pin, GPIO_PIN_RESET);

  /*Configure GPIO pin Output Level */
  HAL_GPIO_WritePin(RS485_DE_GPIO_Port, RS485_DE_Pin, GPIO_PIN_RESET);

  /*Configure GPIO pins : LED_A_Pin LED_B_Pin */
  GPIO_InitStruct.Pin = LED_A_Pin|LED_B_Pin;
  GPIO_InitStruct.Mode = GPIO_MODE_OUTPUT_PP;
  GPIO_InitStruct.Pull = GPIO_NOPULL;
  GPIO_InitStruct.Speed = GPIO_SPEED_FREQ_LOW;
  HAL_GPIO_Init(GPIOE, &GPIO_InitStruct);

  /*Configure GPIO pins : PWRKEY_CON_Pin PWR_EN_Pin */
  GPIO_InitStruct.Pin = PWRKEY_CON_Pin|PWR_EN_Pin;
  GPIO_InitStruct.Mode = GPIO_MODE_OUTPUT_PP;
  GPIO_InitStruct.Pull = GPIO_NOPULL;
  GPIO_InitStruct.Speed = GPIO_SPEED_FREQ_LOW;
  HAL_GPIO_Init(GPIOG, &GPIO_InitStruct);

  /*Configure GPIO pin : RS485_DE_Pin */
  GPIO_InitStruct.Pin = RS485_DE_Pin;
  GPIO_InitStruct.Mode = GPIO_MODE_OUTPUT_PP;
  GPIO_InitStruct.Pull = GPIO_NOPULL;
  GPIO_InitStruct.Speed = GPIO_SPEED_FREQ_LOW;
  HAL_GPIO_Init(RS485_DE_GPIO_Port, &GPIO_InitStruct);

}

/* FSMC initialization function */
static void MX_FSMC_Init(void)
{

  FSMC_NORSRAM_TimingTypeDef Timing = {0};

  /** Perform the SRAM1 memory initialization sequence
  */
  hsram1.Instance = FSMC_NORSRAM_DEVICE;
  hsram1.Extended = FSMC_NORSRAM_EXTENDED_DEVICE;
  /* hsram1.Init */
  hsram1.Init.NSBank = FSMC_NORSRAM_BANK3;
  hsram1.Init.DataAddressMux = FSMC_DATA_ADDRESS_MUX_DISABLE;
  hsram1.Init.MemoryType = FSMC_MEMORY_TYPE_SRAM;
  hsram1.Init.MemoryDataWidth = FSMC_NORSRAM_MEM_BUS_WIDTH_16;
  hsram1.Init.BurstAccessMode = FSMC_BURST_ACCESS_MODE_DISABLE;
  hsram1.Init.WaitSignalPolarity = FSMC_WAIT_SIGNAL_POLARITY_LOW;
  hsram1.Init.WrapMode = FSMC_WRAP_MODE_DISABLE;
  hsram1.Init.WaitSignalActive = FSMC_WAIT_TIMING_BEFORE_WS;
  hsram1.Init.WriteOperation = FSMC_WRITE_OPERATION_DISABLE;
  hsram1.Init.WaitSignal = FSMC_WAIT_SIGNAL_DISABLE;
  hsram1.Init.ExtendedMode = FSMC_EXTENDED_MODE_DISABLE;
  hsram1.Init.AsynchronousWait = FSMC_ASYNCHRONOUS_WAIT_DISABLE;
  hsram1.Init.WriteBurst = FSMC_WRITE_BURST_DISABLE;
  hsram1.Init.PageSize = FSMC_PAGE_SIZE_NONE;
  /* Timing */
  Timing.AddressSetupTime = 15;
  Timing.AddressHoldTime = 15;
  Timing.DataSetupTime = 255;
  Timing.BusTurnAroundDuration = 15;
  Timing.CLKDivision = 16;
  Timing.DataLatency = 17;
  Timing.AccessMode = FSMC_ACCESS_MODE_A;
  /* ExtTiming */

  if (HAL_SRAM_Init(&hsram1, &Timing, NULL) != HAL_OK)
  {
    Error_Handler( );
  }

}

void StartDefaultTask(void *argument)
{

  /* USER CODE BEGIN 5 */

  uint8_t liu_test[10];
  liu_test[0] = 0x43;
  liu_test[9] = 0xab;
  appMsg.src = SysMsgSrc_Thread;
  // appMsg->thread->id = APP_MSG_Start;
  appMsg.thread.id = APP_MSG_Start;
  appMsg.thread.msg = liu_test;
  app.AppStatus = taskStarted;
  osMessageQueuePut(appMsgHandle,&appMsg,NULL,osWaitForever);
  osTimerStart(defultTimer01Handle,500);
  /* Infinite loop */
  for(;;)
  {

    HAL_GPIO_TogglePin(LED_A_GPIO_Port,LED_A_Pin);
    HAL_RTC_GetTime(&hrtc,&rtcTime,RTC_FORMAT_BCD);
    HAL_RTC_GetDate(&hrtc,&rtcDate,RTC_FORMAT_BCD);
    // LOGA("20%d-%d-%d %d:%d:%d",rtcDate.Year,rtcDate.Month,rtcDate.Date,rtcTime.Hours,rtcTime.Minutes,rtcTime.Seconds);
    // HAL_GPIO_TogglePin(LED_B_GPIO_Port,LED_B_Pin);
    osDelay(1000);
  }
  /* USER CODE END 5 */
}

/* Callback01 function */
void Callback01(void *argument) // for v2
{
  /* USER CODE BEGIN Callback01 */
  // HAL_GPIO_TogglePin(LED_B_GPIO_Port,LED_B_Pin);
  /* USER CODE END Callback01 */
}

void HAL_TIM_PeriodElapsedCallback(TIM_HandleTypeDef *htim)
{
  if (htim->Instance == TIM14) {
    HAL_IncTick();
  }
}

void Error_Handler(void)
{
}

/************************ (C) COPYRIGHT STMicroelectronics *****END OF FILE****/

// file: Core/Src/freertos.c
/* USER CODE BEGIN Header */
/**
  ******************************************************************************
  * File Name          : freertos.c
  * Description        : Code for freertos applications
  ******************************************************************************
  * @attention
  *
  * <h2><center>&copy; Copyright (c) 2019 STMicroelectronics.
  * All rights reserved.</center></h2>
  *
  * This software component is licensed by ST under Ultimate Liberty license
  * SLA0044, the "License"; You may not use this file except in compliance with
  * the License. You may obtain a copy of the License at:
  *                             www.st.com/SLA0044
  *
  ******************************************************************************
  */
/* USER CODE END Header */

#include "FreeRTOS.h"
#include "task.h"
#include "main.h"

/* Pre/Post sleep processing prototypes */
void PreSleepProcessing(uint32_t *ulExpectedIdleTime);
void PostSleepProcessing(uint32_t *ulExpectedIdleTime);

/* Hook prototypes */
void configureTimerForRunTimeStats(void);
unsigned long getRunTimeCounterValue(void);

/* USER CODE BEGIN 1 */
/* Functions needed when configGENERATE_RUN_TIME_STATS is on */
__weak void configureTimerForRunTimeStats(void)
{

}

__weak unsigned long getRunTimeCounterValue(void)
{
return 0;
}
/* USER CODE END 1 */

/* USER CODE BEGIN PREPOSTSLEEP */
__weak void PreSleepProcessing(uint32_t *ulExpectedIdleTime)
{
/* place for user code */
}

__weak void PostSleepProcessing(uint32_t *ulExpectedIdleTime)
{
/* place for user code */
}
/* USER CODE END PREPOSTSLEEP */

/************************ (C) COPYRIGHT STMicroelectronics *****END OF FILE****/
